# ICSSM_ICSSM_PR1_CFG_SLV_48026000h register map
Vendor: Texas Instruments
Peripheral module from a debugger description file (folder AM263X).
Registers are 32-bit, access not given, reset 0x0 unless marked. A register's access mark holds for its fields unless they carry their own. Offsets are as the file gives them; lines under a group give offsets from that group; [hi:lo] are bit positions; {n}, {i} and the like mark numbered series; 'fields as' and 'values as' point back to an identical list; <NAME> marks a mode.

## ICSSM_PR1_CFG_SLV
0x00 ICSSM_PR1_CFG_SLV_PID_REG ro reset 0x6B080203
  [31:0] ICSS_IDVER — Module ID field
0x04 ICSSM_PR1_CFG_SLV_HWDIS_REG ro
  [7:0] HWDIS — HW Disable Observation
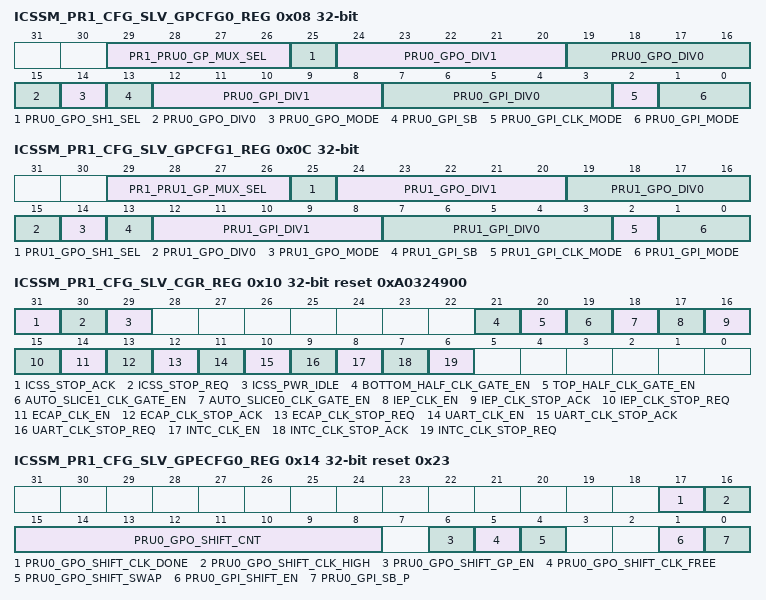
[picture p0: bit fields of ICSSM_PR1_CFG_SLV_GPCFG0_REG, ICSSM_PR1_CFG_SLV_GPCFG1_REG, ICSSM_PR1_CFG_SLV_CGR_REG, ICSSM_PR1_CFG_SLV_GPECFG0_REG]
0x08 ICSSM_PR1_CFG_SLV_GPCFG0_REG
  [29:26] PR1_PRU0_GP_MUX_SEL rw
  [25] PRU0_GPO_SH1_SEL ro
  [24:20] PRU0_GPO_DIV1 rw
  [19:15] PRU0_GPO_DIV0 rw
  [14] PRU0_GPO_MODE rw
  [13] PRU0_GPI_SB — (access R/W1TC)
  [12:8] PRU0_GPI_DIV1 rw
  [7:3] PRU0_GPI_DIV0 rw
  [2] PRU0_GPI_CLK_MODE rw
  [1:0] PRU0_GPI_MODE rw
0x0C ICSSM_PR1_CFG_SLV_GPCFG1_REG
  [29:26] PR1_PRU1_GP_MUX_SEL rw
  [25] PRU1_GPO_SH1_SEL ro
  [24:20] PRU1_GPO_DIV1 rw
  [19:15] PRU1_GPO_DIV0 rw
  [14] PRU1_GPO_MODE rw
  [13] PRU1_GPI_SB — (access R/W1TC)
  [12:8] PRU1_GPI_DIV1 rw
  [7:3] PRU1_GPI_DIV0 rw
  [2] PRU1_GPI_CLK_MODE rw
  [1:0] PRU1_GPI_MODE rw
0x10 ICSSM_PR1_CFG_SLV_CGR_REG access per field reset 0xA0324900
  [31] ICSS_STOP_ACK rw, [30] ICSS_STOP_REQ ro, [29] ICSS_PWR_IDLE rw, [21] BOTTOM_HALF_CLK_GATE_EN rw, [20] TOP_HALF_CLK_GATE_EN rw, [19] AUTO_SLICE1_CLK_GATE_EN rw, [18] AUTO_SLICE0_CLK_GATE_EN rw, [17] IEP_CLK_EN rw, [16] IEP_CLK_STOP_ACK ro, [15] IEP_CLK_STOP_REQ rw, [14] ECAP_CLK_EN rw, [13] ECAP_CLK_STOP_ACK ro, [12] ECAP_CLK_STOP_REQ rw, [11] UART_CLK_EN rw, [10] UART_CLK_STOP_ACK ro, [9] UART_CLK_STOP_REQ rw, [8] INTC_CLK_EN rw, [7] INTC_CLK_STOP_ACK ro, [6] INTC_CLK_STOP_REQ rw
0x14 ICSSM_PR1_CFG_SLV_GPECFG0_REG reset 0x23
  [17] PRU0_GPO_SHIFT_CLK_DONE — (access R/W1C)
  [16] PRU0_GPO_SHIFT_CLK_HIGH rw
  [15:8] PRU0_GPO_SHIFT_CNT rw
  [6] PRU0_GPO_SHIFT_GP_EN rw
  [5] PRU0_GPO_SHIFT_CLK_FREE rw
  [4] PRU0_GPO_SHIFT_SWAP rw
  [1] PRU0_GPI_SHIFT_EN rw
  [0] PRU0_GPI_SB_P rw
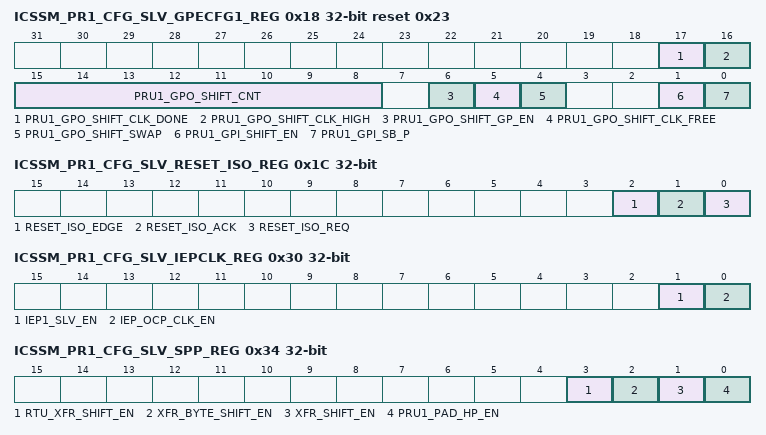
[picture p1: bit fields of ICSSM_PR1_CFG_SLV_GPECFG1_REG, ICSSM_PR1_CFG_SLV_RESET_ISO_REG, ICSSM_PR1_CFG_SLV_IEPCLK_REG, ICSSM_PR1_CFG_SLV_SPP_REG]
0x18 ICSSM_PR1_CFG_SLV_GPECFG1_REG reset 0x23
  [17] PRU1_GPO_SHIFT_CLK_DONE — (access R/W1C)
  [16] PRU1_GPO_SHIFT_CLK_HIGH rw
  [15:8] PRU1_GPO_SHIFT_CNT rw
  [6] PRU1_GPO_SHIFT_GP_EN rw
  [5] PRU1_GPO_SHIFT_CLK_FREE rw
  [4] PRU1_GPO_SHIFT_SWAP rw
  [1] PRU1_GPI_SHIFT_EN rw
  [0] PRU1_GPI_SB_P rw
0x1C ICSSM_PR1_CFG_SLV_RESET_ISO_REG
  [2] RESET_ISO_EDGE wo
  [1] RESET_ISO_ACK wo
  [0] RESET_ISO_REQ — (access R/W1C)
0x2C ICSSM_PR1_CFG_SLV_MII_RT_REG rw reset 0x1
  [0] MII_RT_EVENT_EN
0x30 ICSSM_PR1_CFG_SLV_IEPCLK_REG rw
  [1] IEP1_SLV_EN, [0] IEP_OCP_CLK_EN
0x34 ICSSM_PR1_CFG_SLV_SPP_REG rw
  [3] RTU_XFR_SHIFT_EN, [2] XFR_BYTE_SHIFT_EN, [1] XFR_SHIFT_EN, [0] PRU1_PAD_HP_EN
0x38 ICSSM_PR1_CFG_SLV_SPIN_CFG_REG rw
  [0] SPIN_CLOCK_TX_PRU_EN
0x3C ICSSM_PR1_CFG_SLV_CORE_SYNC_REG rw
  [0] CORE_VBUSP_SYNC_EN
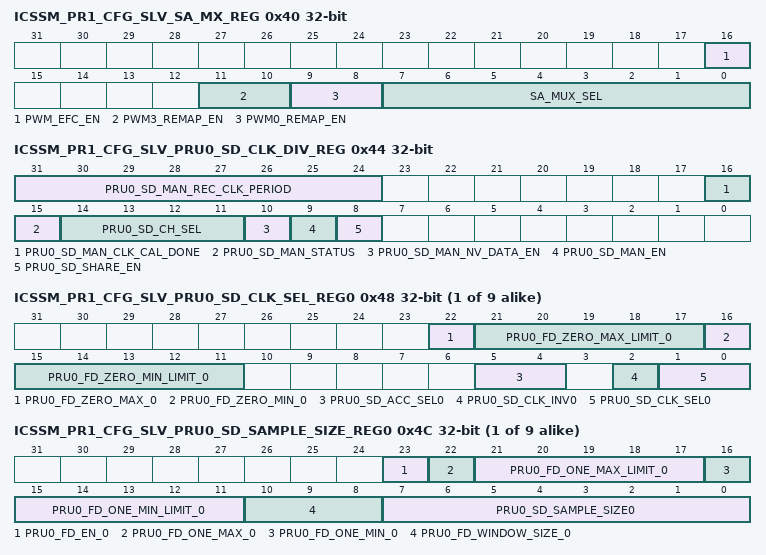
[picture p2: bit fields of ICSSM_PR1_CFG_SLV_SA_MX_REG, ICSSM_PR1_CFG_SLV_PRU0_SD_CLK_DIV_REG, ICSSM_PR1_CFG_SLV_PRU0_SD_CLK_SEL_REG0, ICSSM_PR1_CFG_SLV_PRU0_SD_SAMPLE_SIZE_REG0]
0x40 ICSSM_PR1_CFG_SLV_SA_MX_REG rw
  [16] PWM_EFC_EN, [11:10] PWM3_REMAP_EN, [9:8] PWM0_REMAP_EN, [7:0] SA_MUX_SEL
0x44 ICSSM_PR1_CFG_SLV_PRU0_SD_CLK_DIV_REG access per field
  [31:24] PRU0_SD_MAN_REC_CLK_PERIOD ro, [16] PRU0_SD_MAN_CLK_CAL_DONE ro, [15] PRU0_SD_MAN_STATUS ro, [14:11] PRU0_SD_CH_SEL rw, [10] PRU0_SD_MAN_NV_DATA_EN rw, [9] PRU0_SD_MAN_EN rw, [8] PRU0_SD_SHARE_EN rw
{0x48+8i} ICSSM_PR1_CFG_SLV_PRU0_SD_CLK_SEL_REG{i} (i=0..8)
  [22] PRU0_FD_ZERO_MAX_{i} — (access R/W1C)
  [21:17] PRU0_FD_ZERO_MAX_LIMIT_{i} rw
  [16] PRU0_FD_ZERO_MIN_{i} — (access R/W1C)
  [15:11] PRU0_FD_ZERO_MIN_LIMIT_{i} rw
  [5:4] PRU0_SD_ACC_SEL{i} rw
  [2] PRU0_SD_CLK_INV{i} rw
  [1:0] PRU0_SD_CLK_SEL{i} rw
{0x4C+8i} ICSSM_PR1_CFG_SLV_PRU0_SD_SAMPLE_SIZE_REG{i} (i=0..8)
  [23] PRU0_FD_EN_{i} rw
  [22] PRU0_FD_ONE_MAX_{i} — (access R/W1C)
  [21:17] PRU0_FD_ONE_MAX_LIMIT_{i} rw
  [16] PRU0_FD_ONE_MIN_{i} — (access R/W1C)
  [15:11] PRU0_FD_ONE_MIN_LIMIT_{i} rw
  [10:8] PRU0_FD_WINDOW_SIZE_{i} rw
  [7:0] PRU0_SD_SAMPLE_SIZE{i} rw
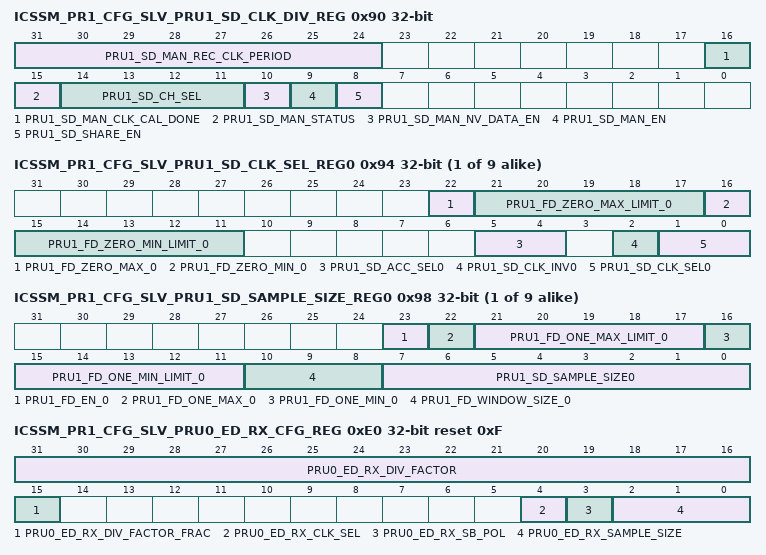
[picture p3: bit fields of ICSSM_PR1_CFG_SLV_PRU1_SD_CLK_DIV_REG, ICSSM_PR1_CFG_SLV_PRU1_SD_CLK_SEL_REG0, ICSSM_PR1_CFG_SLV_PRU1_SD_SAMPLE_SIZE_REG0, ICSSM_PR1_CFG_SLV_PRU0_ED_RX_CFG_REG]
0x90 ICSSM_PR1_CFG_SLV_PRU1_SD_CLK_DIV_REG access per field
  [31:24] PRU1_SD_MAN_REC_CLK_PERIOD ro, [16] PRU1_SD_MAN_CLK_CAL_DONE ro, [15] PRU1_SD_MAN_STATUS ro, [14:11] PRU1_SD_CH_SEL rw, [10] PRU1_SD_MAN_NV_DATA_EN rw, [9] PRU1_SD_MAN_EN rw, [8] PRU1_SD_SHARE_EN rw
{0x94+8i} ICSSM_PR1_CFG_SLV_PRU1_SD_CLK_SEL_REG{i} (i=0..8)
  [22] PRU1_FD_ZERO_MAX_{i} — (access R/W1C)
  [21:17] PRU1_FD_ZERO_MAX_LIMIT_{i} rw
  [16] PRU1_FD_ZERO_MIN_{i} — (access R/W1C)
  [15:11] PRU1_FD_ZERO_MIN_LIMIT_{i} rw
  [5:4] PRU1_SD_ACC_SEL{i} rw
  [2] PRU1_SD_CLK_INV{i} rw
  [1:0] PRU1_SD_CLK_SEL{i} rw
{0x98+8i} ICSSM_PR1_CFG_SLV_PRU1_SD_SAMPLE_SIZE_REG{i} (i=0..8)
  [23] PRU1_FD_EN_{i} rw
  [22] PRU1_FD_ONE_MAX_{i} — (access R/W1C)
  [21:17] PRU1_FD_ONE_MAX_LIMIT_{i} rw
  [16] PRU1_FD_ONE_MIN_{i} — (access R/W1C)
  [15:11] PRU1_FD_ONE_MIN_LIMIT_{i} rw
  [10:8] PRU1_FD_WINDOW_SIZE_{i} rw
  [7:0] PRU1_SD_SAMPLE_SIZE{i} rw
0xE0 ICSSM_PR1_CFG_SLV_PRU0_ED_RX_CFG_REG rw reset 0xF
  [31:16] PRU0_ED_RX_DIV_FACTOR, [15] PRU0_ED_RX_DIV_FACTOR_FRAC, [4] PRU0_ED_RX_CLK_SEL, [3] PRU0_ED_RX_SB_POL, [2:0] PRU0_ED_RX_SAMPLE_SIZE
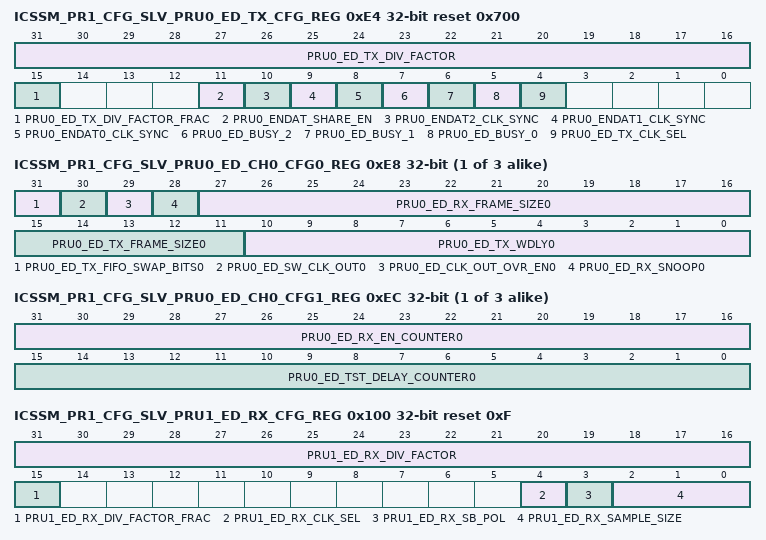
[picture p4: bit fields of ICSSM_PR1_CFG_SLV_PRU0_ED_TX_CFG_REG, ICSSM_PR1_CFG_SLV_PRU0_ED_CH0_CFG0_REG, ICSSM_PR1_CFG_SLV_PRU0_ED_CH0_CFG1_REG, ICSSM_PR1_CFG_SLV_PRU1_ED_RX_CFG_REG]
0xE4 ICSSM_PR1_CFG_SLV_PRU0_ED_TX_CFG_REG access per field reset 0x700
  [31:16] PRU0_ED_TX_DIV_FACTOR rw, [15] PRU0_ED_TX_DIV_FACTOR_FRAC rw, [11] PRU0_ENDAT_SHARE_EN rw, [10] PRU0_ENDAT2_CLK_SYNC ro, [9] PRU0_ENDAT1_CLK_SYNC ro, [8] PRU0_ENDAT0_CLK_SYNC ro, [7] PRU0_ED_BUSY_2 ro, [6] PRU0_ED_BUSY_1 ro, [5] PRU0_ED_BUSY_0 ro, [4] PRU0_ED_TX_CLK_SEL rw
{0xE8+8i} ICSSM_PR1_CFG_SLV_PRU0_ED_CH{i}_CFG0_REG access per field (i=0..2)
  [31] PRU0_ED_TX_FIFO_SWAP_BITS{i} rw, [30] PRU0_ED_SW_CLK_OUT{i} rw, [29] PRU0_ED_CLK_OUT_OVR_EN{i} rw, [28] PRU0_ED_RX_SNOOP{i} ro, [27:16] PRU0_ED_RX_FRAME_SIZE{i} rw, [15:11] PRU0_ED_TX_FRAME_SIZE{i} rw, [10:0] PRU0_ED_TX_WDLY{i} rw
{0xEC+8i} ICSSM_PR1_CFG_SLV_PRU0_ED_CH{i}_CFG1_REG rw (i=0..2)
  [31:16] PRU0_ED_RX_EN_COUNTER{i}, [15:0] PRU0_ED_TST_DELAY_COUNTER{i}
0x100 ICSSM_PR1_CFG_SLV_PRU1_ED_RX_CFG_REG rw reset 0xF
  [31:16] PRU1_ED_RX_DIV_FACTOR, [15] PRU1_ED_RX_DIV_FACTOR_FRAC, [4] PRU1_ED_RX_CLK_SEL, [3] PRU1_ED_RX_SB_POL, [2:0] PRU1_ED_RX_SAMPLE_SIZE
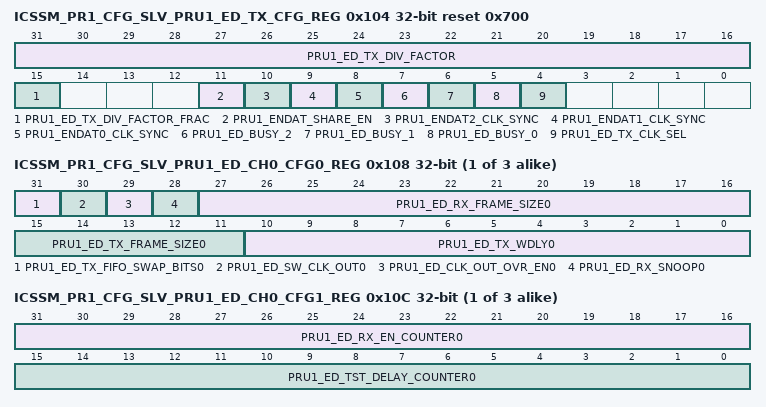
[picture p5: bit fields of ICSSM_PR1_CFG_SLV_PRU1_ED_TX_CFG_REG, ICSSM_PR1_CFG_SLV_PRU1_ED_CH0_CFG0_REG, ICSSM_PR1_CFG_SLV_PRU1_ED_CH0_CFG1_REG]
0x104 ICSSM_PR1_CFG_SLV_PRU1_ED_TX_CFG_REG access per field reset 0x700
  [31:16] PRU1_ED_TX_DIV_FACTOR rw, [15] PRU1_ED_TX_DIV_FACTOR_FRAC rw, [11] PRU1_ENDAT_SHARE_EN rw, [10] PRU1_ENDAT2_CLK_SYNC ro, [9] PRU1_ENDAT1_CLK_SYNC ro, [8] PRU1_ENDAT0_CLK_SYNC ro, [7] PRU1_ED_BUSY_2 ro, [6] PRU1_ED_BUSY_1 ro, [5] PRU1_ED_BUSY_0 ro, [4] PRU1_ED_TX_CLK_SEL rw
{0x108+8i} ICSSM_PR1_CFG_SLV_PRU1_ED_CH{i}_CFG0_REG access per field (i=0..2)
  [31] PRU1_ED_TX_FIFO_SWAP_BITS{i} rw, [30] PRU1_ED_SW_CLK_OUT{i} rw, [29] PRU1_ED_CLK_OUT_OVR_EN{i} rw, [28] PRU1_ED_RX_SNOOP{i} ro, [27:16] PRU1_ED_RX_FRAME_SIZE{i} rw, [15:11] PRU1_ED_TX_FRAME_SIZE{i} rw, [10:0] PRU1_ED_TX_WDLY{i} rw
{0x10C+8i} ICSSM_PR1_CFG_SLV_PRU1_ED_CH{i}_CFG1_REG rw (i=0..2)
  [31:16] PRU1_ED_RX_EN_COUNTER{i}, [15:0] PRU1_ED_TST_DELAY_COUNTER{i}
0x124 ICSSM_PR1_CFG_SLV_RTU0_POKE_EN0_REG reset not defined
0x12C ICSSM_PR1_CFG_SLV_RTU1_POKE_EN0_REG reset not defined
{0x130+4i} ICSSM_PR1_CFG_SLV_PWM{i} reset not defined (i=0..3)
{0x140+0xC*i} ICSSM_PR1_CFG_SLV_PWM{i}_0 reset not defined (i=0..3)
{0x144+0xC*i} ICSSM_PR1_CFG_SLV_PWM{i}_1 reset not defined (i=0..3)
{0x148+0xC*i} ICSSM_PR1_CFG_SLV_PWM{i}_2 reset not defined (i=0..3)
0x170 ICSSM_PR1_CFG_SLV_SPIN_LOCK0 reset not defined
0x174 ICSSM_PR1_CFG_SLV_SPIN_LOCK1 reset not defined
{0x178+8i} ICSSM_PR1_CFG_SLV_PA_STAT_PDSP_CFG{i} reset not defined (i=0..3)
{0x17C+8i} ICSSM_PR1_CFG_SLV_PA_STAT_PDSP_STAT{i} reset not defined (i=0..3)
